# EG32M0x register map
Vendor: EGmicro Ltd.; Series: EG32M0x; File version: 1.0
CPU: CM0 r0p0, little endian, no MPU, no FPU, 3 interrupt priority bits
Registers are 32-bit, read-write, reset 0x0 unless marked. A register's access mark holds for its fields unless they carry their own. Offsets are from the block's base; [hi:lo] are bit positions; {n}, {i} and the like mark numbered series.

## TIMER1 — TIMER1 unit
Base 0x40020400
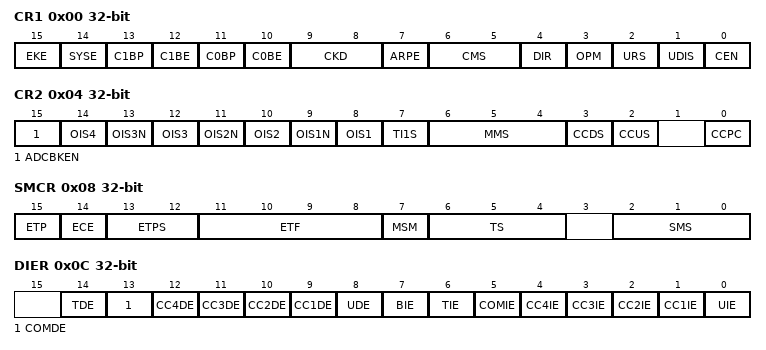
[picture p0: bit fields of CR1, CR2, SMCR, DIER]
0x00 CR1
  [15] EKE — External IO brake input switch
  [14] SYSE — System error brake switch
  [13] C1BP — Comparator 1 brake polarity
  [12] C1BE — Comparator 1 brake switch
  [11] C0BP — Comparator 0 brake polarity
  [10] C0BE — Comparator 0 brake switch
  [9:8] CKD — Clock frequency division factor
  [7] ARPE — Automatic reloading preloading allows bits
  [6:5] CMS — Select the center alignment mode
  [4] DIR — Counting direction
  [3] OPM — Single pulse mode
  [2] URS — Update request source
  [1] UDIS — Forbid updating
  [0] CEN — Enable counter
0x04 CR2
  [15] ADCBKEN — ADC brake switch
  [2n+6] OIS{n} (n=1..4) — Output idle status {n}
  [13] OIS3N — Output idle status 3
  [11] OIS2N — Output idle status 2
  [9] OIS1N — Output idle status 1
  [7] TI1S — TI1 selection
  [6:4] MMS — Master mode selection
  [3] CCDS — DMA selection for capture/comparison
  [2] CCUS — Capture/compare control update selection
  [0] CCPC — Capture/compare preloaded control bits
0x08 SMCR
  [15] ETP — External trigger polarity
  [14] ECE — External clock enable bit
  [13:12] ETPS — External trigger predivision
  [11:8] ETF — External trigger filtering
  [7] MSM — Master/slave mode
  [6:4] TS — Trigger selection
  [2:0] SMS — Mode selection
0x0C DIER
  [14] TDE — Allows DMA requests to be triggered
  [13] COMDE — DMA requests for COM are allowed
  [n+8] CC{n}DE (n=1..4) — DMA requests for capture/compare {n} are allowed
  [8] UDE — DMA requests that allow updates
  [7] BIE — Allow brake break
  [6] TIE — The interrupt function was triggered
  [5] COMIE — Allow COM interrupt
  [n] CC{n}IE (n=1..4) — Allows capture/compare {n} interrupts
  [0] UIE — Allow update interrupt
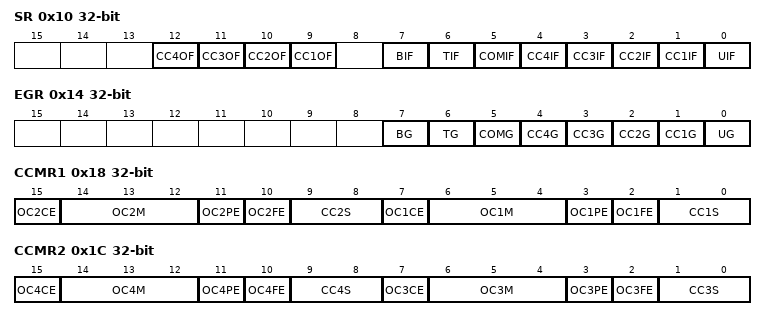
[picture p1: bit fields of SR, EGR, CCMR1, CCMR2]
0x10 SR
  [n+8] CC{n}OF (n=1..4) — Capture {n} Repeat the capture tag
  [7] BIF — Brake interrupt flag
  [6] TIF — Trigger interrupt flag
  [5] COMIF — COM interrupt flag
  [n] CC{n}IF (n=1..4) — Capture/compare {n} interrupt flags
  [0] UIF — Update interrupt flag
0x14 EGR
  [7] BG — Generating brake event
  [6] TG — Generate trigger event
  [5] COMG — Capture/compare event generation control updates
  [n] CC{n}G (n=1..4) — Generate the capture/Compare {n} event
  [0] UG — Generate update event
0x18 CCMR1
  [15] OC2CE — Output comparison 2 Clear 0 enable
  [14:12] OC2M — Output comparison 2 mode
  [11] OC2PE — Output comparison 2 Preload enable
  [10] OC2FE — Output comparison 2 Fast enable
  [9:8] CC2S — Capture/Compare 2 Select
  [7] OC1CE — Output comparison 1 Clear 0 enable
  [6:4] OC1M — Output comparison 1 mode
  [3] OC1PE — Output comparison 1 Preload enable
  [2] OC1FE — Output comparison 1 Fast enable
  [1:0] CC1S — Capture/Compare 1 Select
0x1C CCMR2
  [15] OC4CE — Output comparison 4 clear 0 enabled
  [14:12] OC4M — Output comparison 4 mode
  [11] OC4PE — Output comparison 4 Preload enable
  [10] OC4FE — Compare the output 4 Fast enable
  [9:8] CC4S — Capture/Compare 4 Select
  [7] OC3CE — Output comparison 3 clear 0 enabled
  [6:4] OC3M — Output comparison 3 mode
  [3] OC3PE — Output comparison 3 Preload enable
  [2] OC3FE — Compare the output 3 Fast enable
  [1:0] CC3S — Capture/Compare 3 Select
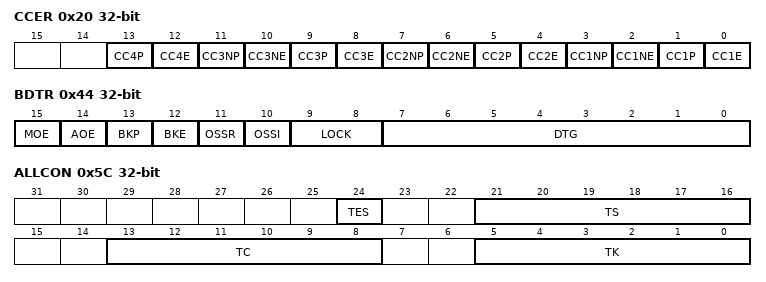
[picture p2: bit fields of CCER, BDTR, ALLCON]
0x20 CCER
  [4n-3] CC{n}P (n=1..4) — Input/Capture {n} Output polarity
  [12] CC4E — Input/Capture 4 Enable the output
  [11] CC3NP — Input/Capture 3 Complementary output polarity
  [10] CC3NE — Input/Capture 3 Enable complementary output
  [8] CC3E — Input/Capture 3 Output Enable
  [7] CC2NP — Input/Capture 2 Complementary output polarity
  [6] CC2NE — Input/Capture 2 Enable complementary output
  [4] CC2E — Input/Capture 2 Output Enable
  [3] CC1NP — Input/Capture 1 Complementary output polarity
  [2] CC1NE — Input/Capture 1 Enable complementary output
  [0] CC1E — Input/Capture 1 Output Enable
0x24 CNT
  [15:0] CNT — Counter value
0x28 PSC
  [15:0] PSC — The value of the pre-divider
0x2C ARR reset 0xFFFF
  [15:0] ARR — The value of automatic reloading
0x30 RCR
  [7:0] REP — Repeat the value of the counter
{0x30+4i} CCR{i} reset 0xFFFF (i=1..4)
  [15:0] CCR{i} — Capture/compare values for channel {i}
0x44 BDTR
  [15] MOE — Master output is enabled
  [14] AOE — Automatic output is enabled
  [13] BKP — External IO brake input polarity
  [12] BKE — The brake function is enabled
  [11] OSSR — Off state in run mode
  [10] OSSI — Off state in idle mode
  [9:8] LOCK — Lock setting
  [7:0] DTG — Dead zone generator setting
0x5C ALLCON
  [24] TES — TIM4/5/6 External IO brake signal selection
  [21:16] TS — TIM1 to TIM6 stops counting
  [13:8] TC — The TIM1 to TIM6 counters were cleared to zero
  [5:0] TK — TIM1 to TIM6 counters are enabled

## TIMER2 — TIMER2 unit
Base 0x40020460
Same registers: TIMER3 0x400204C0
Registers as TIMER1, without RCR, BDTR, ALLCON; these are added or differ:
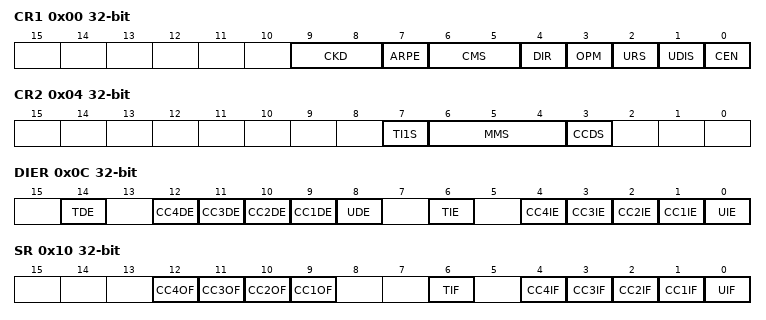
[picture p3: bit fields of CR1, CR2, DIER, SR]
0x00 CR1
  [9:8] CKD — Clock frequency division factor
  [7] ARPE — Automatic reloading preloading allows bits
  [6:5] CMS — Select the center alignment mode
  [4] DIR — Counting direction
  [3] OPM — Single pulse mode
  [2] URS — Update request source
  [1] UDIS — Forbid updating
  [0] CEN — Enable counter
0x04 CR2
  [7] TI1S — TI1 selection
  [6:4] MMS — Master mode selection
  [3] CCDS — DMA selection for capture/comparison
0x0C DIER
  [14] TDE — Allows DMA requests to be triggered
  [n+8] CC{n}DE (n=1..4) — DMA requests for capture/compare {n} are allowed
  [8] UDE — DMA requests that allow updates
  [6] TIE — The interrupt function was triggered
  [n] CC{n}IE (n=1..4) — Allows capture/compare {n} interrupts
  [0] UIE — Allow update interrupt
0x10 SR
  [n+8] CC{n}OF (n=1..4) — Capture {n} Repeat the capture tag
  [6] TIF — Trigger interrupt flag
  [n] CC{n}IF (n=1..4) — Capture/compare {n} interrupt flags
  [0] UIF — Update interrupt flag
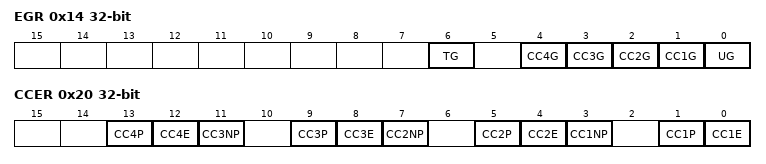
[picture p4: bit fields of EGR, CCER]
0x14 EGR
  [6] TG — Generate trigger event
  [n] CC{n}G (n=1..4) — Generate the capture/Compare {n} event
  [0] UG — Generate update event
0x20 CCER
  [4n-3] CC{n}P (n=1..4) — Input/Capture {n} Output polarity
  [12] CC4E — Input/Capture 4 Enable the output
  [11] CC3NP — Input/Capture 3 Complementary output polarity
  [8] CC3E — Input/Capture 3 Output Enable
  [7] CC2NP — Input/Capture 2 Complementary output polarity
  [4] CC2E — Input/Capture 2 Output Enable
  [3] CC1NP — Input/Capture 1 Complementary output polarity
  [0] CC1E — Input/Capture 1 Output Enable
